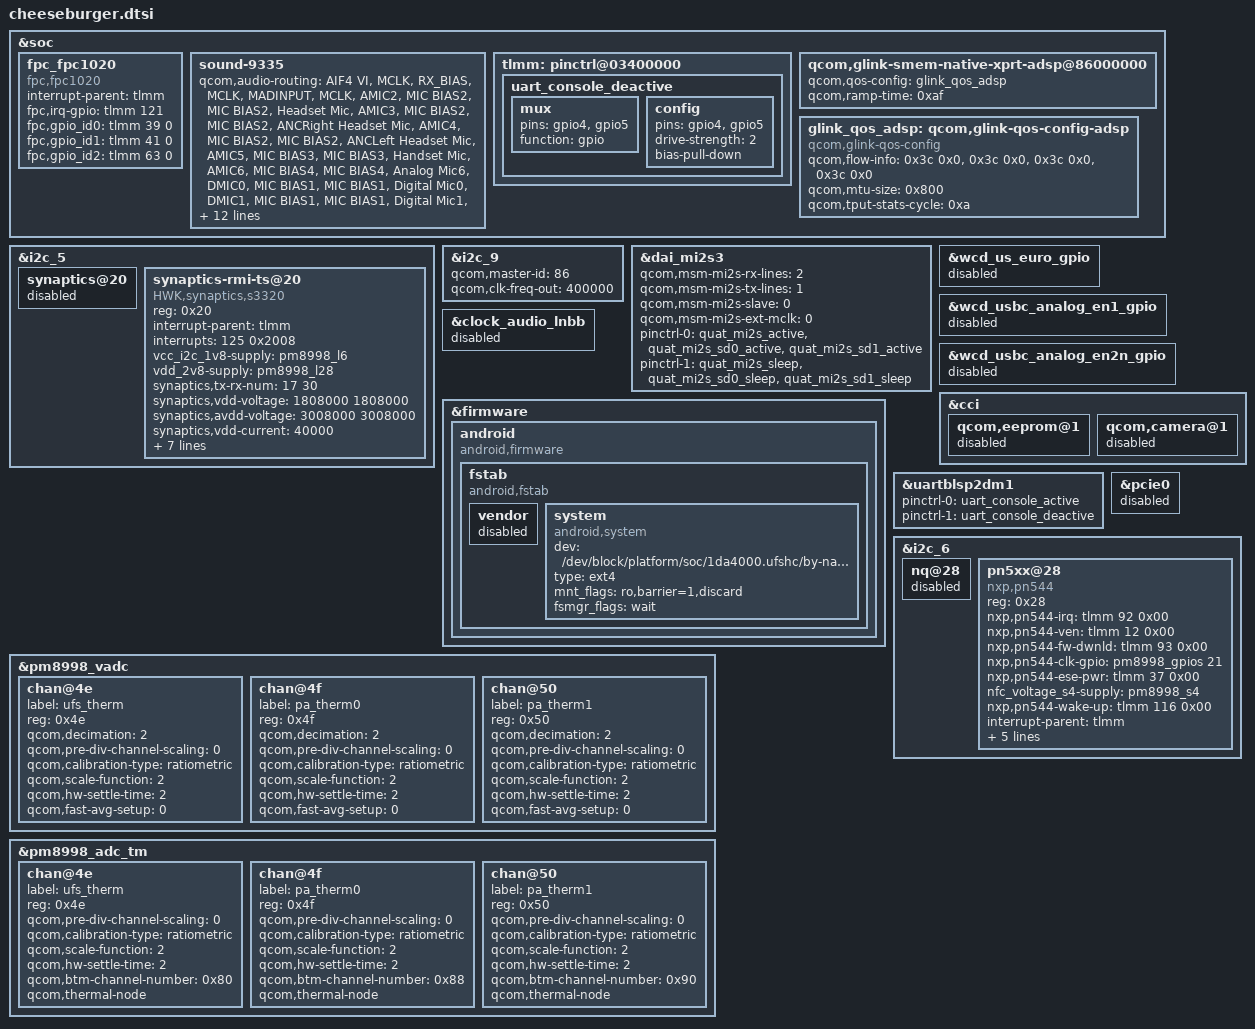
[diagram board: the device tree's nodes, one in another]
/* Copyright (c) 2016-2017, The Linux Foundation. All rights reserved.
 *
 * This program is free software; you can redistribute it and/or modify
 * it under the terms of the GNU General Public License version 2 and
 * only version 2 as published by the Free Software Foundation.
 *
 * This program is distributed in the hope that it will be useful,
 * but WITHOUT ANY WARRANTY; without even the implied warranty of
 * MERCHANTABILITY or FITNESS FOR A PARTICULAR PURPOSE.  See the
 * GNU General Public License for more details.
 */

#include "oneplus5-common.dtsi"

/* I/O */
&soc {

	/* Fingerprint */
	fpc_fpc1020 {
		compatible = "fpc,fpc1020";
		interrupt-parent = <&tlmm>;
		fpc,irq-gpio    = <&tlmm 121 0>;
		fpc,gpio_id0    = <&tlmm 39 0>;
		fpc,gpio_id1    = <&tlmm 41 0>;
		fpc,gpio_id2    = <&tlmm 63 0>;
	};

};

/* Display */
&i2c_5 {
	synaptics@20 {
		status = "disabled";
	};
	synaptics-rmi-ts@20 {
		compatible = "HWK,synaptics,s3320";
		reg = <0x20>;
		interrupt-parent = <&tlmm>;
		interrupts = <125 0x2008>;
		vcc_i2c_1v8-supply = <&pm8998_l6>;
		vdd_2v8-supply = <&pm8998_l28>;
		synaptics,tx-rx-num = <17 30>;
		synaptics,vdd-voltage = <1808000 1808000>;
		synaptics,avdd-voltage = <3008000 3008000>;
		synaptics,vdd-current = <40000>;
		synaptics,avdd-current = <20000>;
		synaptics,display-coords = <1080 1920>;
		synaptics,reset-gpio = <&tlmm 89 0x00>;
		synaptics,irq-gpio = <&tlmm 125 0x2008>;
		oem,support_hw_poweroff;
		pinctrl-names = "pmx_ts_active", "pmx_ts_suspend";
		pinctrl-0 = <&ts_active>;
		pinctrl-1 = <&ts_int_suspend &ts_reset_suspend>;
	};
};

/* Audio */
&soc {
	sound-9335 {
		qcom,audio-routing =
			"AIF4 VI", "MCLK",
			"RX_BIAS", "MCLK",
			"MADINPUT", "MCLK",
			"AMIC2", "MIC BIAS2",
			"MIC BIAS2", "Headset Mic",
			"AMIC3", "MIC BIAS2",
			"MIC BIAS2", "ANCRight Headset Mic",
			"AMIC4", "MIC BIAS2",
			"MIC BIAS2", "ANCLeft Headset Mic",
			"AMIC5", "MIC BIAS3",
			"MIC BIAS3", "Handset Mic",
			"AMIC6", "MIC BIAS4",
			"MIC BIAS4", "Analog Mic6",
			"DMIC0", "MIC BIAS1",
			"MIC BIAS1", "Digital Mic0",
			"DMIC1", "MIC BIAS1",
			"MIC BIAS1", "Digital Mic1",
			"DMIC2", "MIC BIAS4",
			"MIC BIAS4", "Digital Mic2",
			"DMIC3", "MIC BIAS4",
			"MIC BIAS4", "Digital Mic3",
			"DMIC4", "MIC BIAS3",
			"MIC BIAS3", "Digital Mic4",
			"DMIC5", "MIC BIAS3",
			"MIC BIAS3", "Digital Mic5",
			"SpkrLeft IN", "SPK1 OUT",
			"SpkrRight IN", "SPK2 OUT";
		qcom,us-euro-gpios = <>;
		qcom,msm-mbhc-hphl-swh = <1>;
		qcom,msm-mbhc-gnd-swh = <1>;
		qcom,wsa-max-devs = <0>;
		qcom,wsa-devs = <0>;
		qcom,wsa-aux-dev-prefix = <0>;
	};
};

&i2c_9 { /* BLSP2 QUP9 for Audio Speaker */
	qcom,master-id = <86>;
	qcom,clk-freq-out = <400000>;
	status = "ok";
};

&dai_mi2s3 {
	qcom,msm-mi2s-rx-lines = <2>;
	qcom,msm-mi2s-tx-lines = <1>;
	qcom,msm-mi2s-slave = <0>;
	qcom,msm-mi2s-ext-mclk = <0>;
	pinctrl-names = "default", "sleep";
	pinctrl-0 = <&quat_mi2s_active
			&quat_mi2s_sd0_active
			&quat_mi2s_sd1_active>;
	pinctrl-1 = <&quat_mi2s_sleep
			&quat_mi2s_sd0_sleep
			&quat_mi2s_sd1_sleep>;
};

&wcd_us_euro_gpio {
	status = "disabled";
};

&wcd_usbc_analog_en1_gpio {
	status = "disabled";
};

&wcd_usbc_analog_en2n_gpio {
	status = "disabled";
};
&clock_audio_lnbb {
	status = "disabled";
};

/* Camera */
&cci {
	qcom,eeprom@1 {
		status = "disabled";
	};

	qcom,camera@1 {
		status = "disabled";
	};
};


&firmware {
    android {
        compatible = "android,firmware";
        fstab {
            compatible = "android,fstab";
            vendor {
                status = "disabled";
            };

            system {
                compatible = "android,system";
                dev = "/dev/block/platform/soc/1da4000.ufshc/by-name/system";
                type = "ext4";
                mnt_flags = "ro,barrier=1,discard";
                fsmgr_flags = "wait";
                status = "ok";
            };
        };
    };
};

/*Anderson-Config_UARTPIN_as_GPIO*[*/
&soc {
	tlmm: pinctrl@03400000 {
		uart_console_deactive: uart_console_deactive {
			mux {
				pins = "gpio4", "gpio5";
				function = "gpio";
			};

			config {
				pins = "gpio4", "gpio5";
				drive-strength = <2>;
				bias-pull-down;
			};
		};
	};
};

&uartblsp2dm1 {
	pinctrl-names = "uart_active", "uart_deactive";
	pinctrl-0 = <&uart_console_active>;
	pinctrl-1 = <&uart_console_deactive>;
};
/*Anderson-Config_UARTPIN_as_GPIO*]**/

/* External Thermistors */
&pm8998_vadc {
	chan@4e {
		label = "ufs_therm";
		reg = <0x4e>;
		qcom,decimation = <2>;
		qcom,pre-div-channel-scaling = <0>;
		qcom,calibration-type = "ratiometric";
		qcom,scale-function = <2>;
		qcom,hw-settle-time = <2>;
		qcom,fast-avg-setup = <0>;
	};

	chan@4f {
		label = "pa_therm0";
		reg = <0x4f>;
		qcom,decimation = <2>;
		qcom,pre-div-channel-scaling = <0>;
		qcom,calibration-type = "ratiometric";
		qcom,scale-function = <2>;
		qcom,hw-settle-time = <2>;
		qcom,fast-avg-setup = <0>;
	};

	chan@50 {
		label = "pa_therm1";
		reg = <0x50>;
		qcom,decimation = <2>;
		qcom,pre-div-channel-scaling = <0>;
		qcom,calibration-type = "ratiometric";
		qcom,scale-function = <2>;
		qcom,hw-settle-time = <2>;
		qcom,fast-avg-setup = <0>;
	};
};

&pm8998_adc_tm {
	chan@4e {
		label = "ufs_therm";
		reg = <0x4e>;
		qcom,pre-div-channel-scaling = <0>;
		qcom,calibration-type = "ratiometric";
		qcom,scale-function = <2>;
		qcom,hw-settle-time = <2>;
		qcom,btm-channel-number = <0x80>;
		qcom,thermal-node;
	};

	chan@4f {
		label = "pa_therm0";
		reg = <0x4f>;
		qcom,pre-div-channel-scaling = <0>;
		qcom,calibration-type = "ratiometric";
		qcom,scale-function = <2>;
		qcom,hw-settle-time = <2>;
		qcom,btm-channel-number = <0x88>;
		qcom,thermal-node;
	};

	chan@50 {
		label = "pa_therm1";
		reg = <0x50>;
		qcom,pre-div-channel-scaling = <0>;
		qcom,calibration-type = "ratiometric";
		qcom,scale-function = <2>;
		qcom,hw-settle-time = <2>;
		qcom,btm-channel-number = <0x90>;
		qcom,thermal-node;
	};
};
/*  wangdongdong@MultiMediaService,2017/02/23,add adsp qos configuration start
 *  CRs-Fixed: 2009756
 */
&soc {
	qcom,glink-smem-native-xprt-adsp@86000000 {
		qcom,qos-config = <&glink_qos_adsp>;
		qcom,ramp-time = <0xaf>;
	};
	glink_qos_adsp: qcom,glink-qos-config-adsp {
		compatible = "qcom,glink-qos-config";
		qcom,flow-info = <0x3c 0x0>,
				<0x3c 0x0>,
				<0x3c 0x0>,
				<0x3c 0x0>;
		qcom,mtu-size = <0x800>;
		qcom,tput-stats-cycle = <0xa>;
	};
};
/*  wangdongdong@MultiMediaService,2017/02/23,end  */

/*pcie 0 don't used,gpio 37 will used in nfc.*/
/*but gpio37 will request in pcie0. so disable it*/
&pcie0 {
	status = "disabled";
};

&i2c_6 { /* BLSP1 QUP6 (NFC) */
	nq@28 {
		status = "disabled";
	};

	pn5xx@28 {
		compatible = "nxp,pn544";
		reg = <0x28>;
		nxp,pn544-irq = <&tlmm 92 0x00>;
		nxp,pn544-ven = <&tlmm 12 0x00>;
		nxp,pn544-fw-dwnld = <&tlmm 93 0x00>;
		nxp,pn544-clk-gpio = <&pm8998_gpios 21 0x00>;
		nxp,pn544-ese-pwr = <&tlmm 37 0x00>;
		nfc_voltage_s4-supply = <&pm8998_s4>;
		nxp,pn544-wake-up = <&tlmm 116 0x00>;
		interrupt-parent = <&tlmm>;
		qcom,clk-src = "BBCLK3";
		interrupts = <92 0>;
		interrupt-names = "nfc_irq";
		pinctrl-names = "nfc_active", "nfc_suspend";
		pinctrl-0 = <&nfc_int_active &nfc_enable_active>;
		pinctrl-1 = <&nfc_int_suspend &nfc_enable_suspend>;
		clocks = <&clock_gcc clk_ln_bb_clk3_pin>;
		clock-names = "ref_clk";
	};
};
